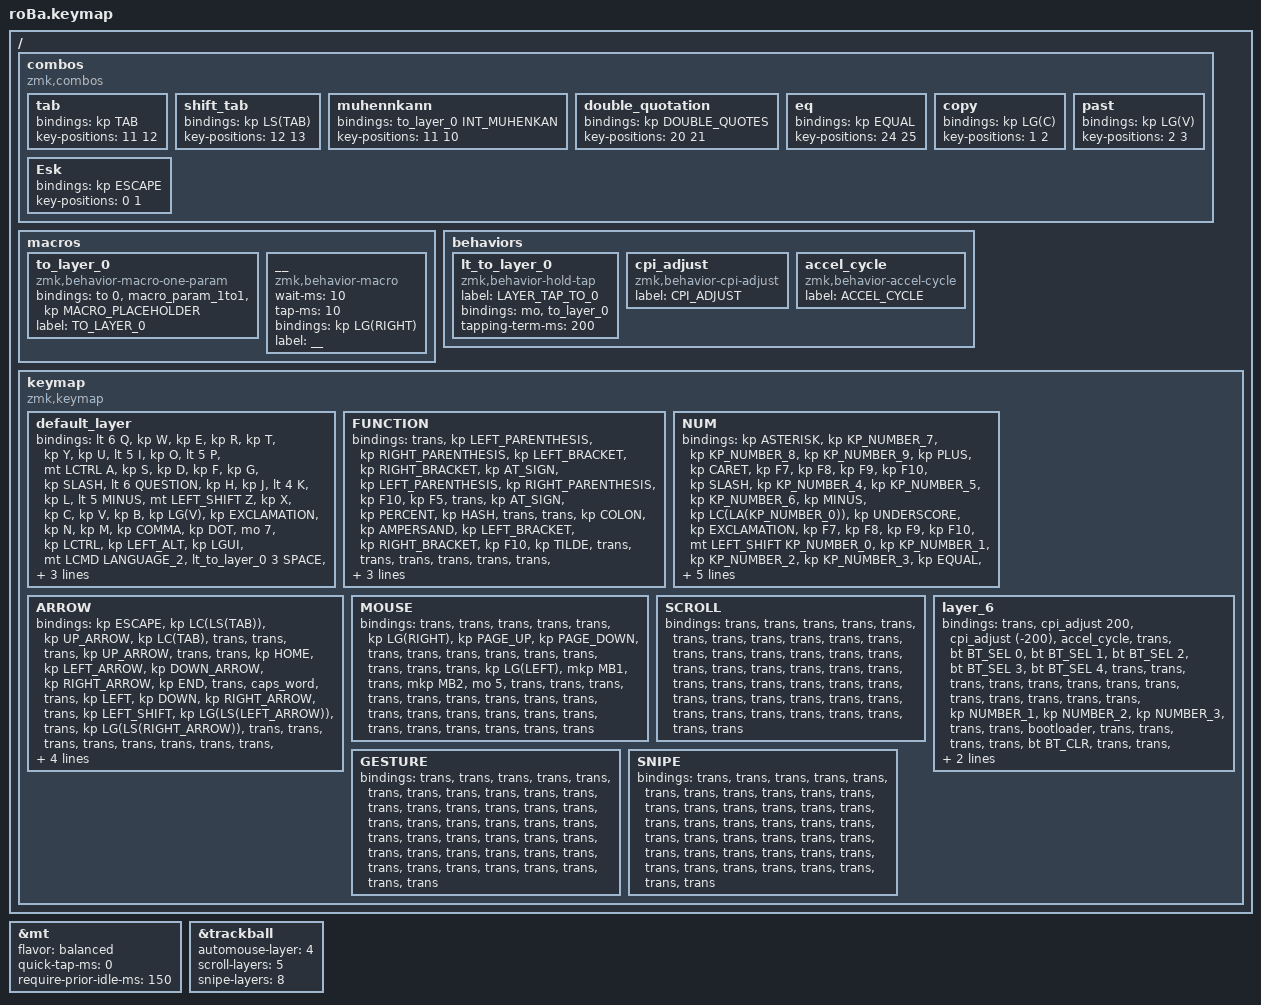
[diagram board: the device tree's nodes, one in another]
#include <behaviors.dtsi>
#include <dt-bindings/zmk/bt.h>
#include <dt-bindings/zmk/keys.h>
#include <dt-bindings/zmk/pointing.h>

&mt {
    flavor = "balanced";
    quick-tap-ms = <0>;
    // 直前のキー操作から150ms以内なら判定せず即タップ扱いにする
    // （高速タイピング中の意図しないホールド誤爆＝寿司打でZが消える問題への対策）
    require-prior-idle-ms = <150>;
};

&trackball {
    automouse-layer = <4>;
    scroll-layers = <5>;
    snipe-layers = <8>;
    // ジェスチャー(ball action)は roBa_R.overlay の trackball@0 内に定義（子ノードはoverlayが正しい置き場所）
};

/ {

    combos {
        compatible = "zmk,combos";

        tab {
            bindings = <&kp TAB>;
            key-positions = <11 12>;
        };

        shift_tab {
            bindings = <&kp LS(TAB)>;
            key-positions = <12 13>;
        };

        muhennkann {
            bindings = <&to_layer_0 INT_MUHENKAN>;
            key-positions = <11 10>;
        };

        double_quotation {
            bindings = <&kp DOUBLE_QUOTES>;
            key-positions = <20 21>;
        };

        eq {
            bindings = <&kp EQUAL>;
            key-positions = <24 25>;
        };

        copy {
            bindings = <&kp LG(C)>;
            key-positions = <1 2>;
        };

        past {
            bindings = <&kp LG(V)>;
            key-positions = <2 3>;
        };

        Esk {
            bindings = <&kp ESCAPE>;
            key-positions = <0 1>;
        };

    };

    macros {
        to_layer_0: to_layer_0 {
            compatible = "zmk,behavior-macro-one-param";
            #binding-cells = <1>;
            bindings = <&to 0 &macro_param_1to1 &kp MACRO_PLACEHOLDER>;
            label = "TO_LAYER_0";
        };
        __: __ {
            compatible = "zmk,behavior-macro";
            #binding-cells = <0>;
            wait-ms = <10>;
            tap-ms = <10>;
            bindings = <&kp LG(RIGHT)>;
            label = "__";
        };
    };

    behaviors {
        lt_to_layer_0: lt_to_layer_0 {
            compatible = "zmk,behavior-hold-tap";
            label = "LAYER_TAP_TO_0";
            bindings = <&mo>, <&to_layer_0>;

            #binding-cells = <2>;
            tapping-term-ms = <200>;
        };

        cpi_adjust: cpi_adjust {
            compatible = "zmk,behavior-cpi-adjust";
            label = "CPI_ADJUST";
            #binding-cells = <1>;
        };

        accel_cycle: accel_cycle {
            compatible = "zmk,behavior-accel-cycle";
            label = "ACCEL_CYCLE";
            #binding-cells = <0>;
        };
    };

    keymap {
        compatible = "zmk,keymap";

        default_layer {
            bindings = <
                &lt 6 Q  &kp W  &kp E  &kp R  &kp T  &kp Y  &kp U  &lt 5 I  &kp O  &lt 5 P  &mt LCTRL A  &kp S  &kp D  &kp F  &kp G  &kp SLASH  &lt 6 QUESTION  &kp H  &kp J  &lt 4 K  &kp L  &lt 5 MINUS  &mt LEFT_SHIFT Z  &kp X  &kp C  &kp V  &kp B  &kp LG(V)  &kp EXCLAMATION  &kp N  &kp M  &kp COMMA  &kp DOT  &mo 7  &kp LCTRL  &kp LEFT_ALT  &kp LGUI  &mt LCMD LANGUAGE_2  &lt_to_layer_0 3 SPACE  &lt_to_layer_0 1 LANG1  &kp BACKSPACE  &lt 2 ENTER  &mo 8
            >;
            sensor-bindings = <&inc_dec_kp PG_UP PAGE_DOWN>;
        };

        FUNCTION {
            bindings = <
                &trans  &kp LEFT_PARENTHESIS  &kp RIGHT_PARENTHESIS  &kp LEFT_BRACKET  &kp RIGHT_BRACKET  &kp AT_SIGN  &kp LEFT_PARENTHESIS  &kp RIGHT_PARENTHESIS  &kp F10  &kp F5  &trans  &kp AT_SIGN  &kp PERCENT  &kp HASH  &trans  &trans  &kp COLON  &kp AMPERSAND  &kp LEFT_BRACKET  &kp RIGHT_BRACKET  &kp F10  &kp TILDE  &trans  &trans  &trans  &trans  &trans  &trans  &kp SEMICOLON  &kp UNDERSCORE  &trans  &trans  &trans  &kp F11  &trans  &trans  &trans  &trans  &trans  &trans  &trans  &trans  &kp F12
            >;
        };

        NUM {
            bindings = <
                &kp ASTERISK  &kp KP_NUMBER_7  &kp KP_NUMBER_8  &kp KP_NUMBER_9  &kp PLUS  &kp CARET  &kp F7  &kp F8  &kp F9  &kp F10  &kp SLASH  &kp KP_NUMBER_4  &kp KP_NUMBER_5  &kp KP_NUMBER_6  &kp MINUS  &kp LC(LA(KP_NUMBER_0))  &kp UNDERSCORE  &kp EXCLAMATION  &kp F7  &kp F8  &kp F9  &kp F10  &mt LEFT_SHIFT KP_NUMBER_0  &kp KP_NUMBER_1  &kp KP_NUMBER_2  &kp KP_NUMBER_3  &kp EQUAL  &kp EQUAL  &kp COLON  &kp LEFT_BRACKET  &kp RIGHT_BRACKET  &kp LEFT_BRACE  &kp RIGHT_BRACE  &kp BACKSLASH  &trans  &trans  &trans  &kp KP_NUMBER_0  &trans  &trans  &trans  &trans  &kp PIPE
            >;
        };

        ARROW {
            bindings = <
                &kp ESCAPE  &kp LC(LS(TAB))  &kp UP_ARROW  &kp LC(TAB)  &trans  &trans  &trans  &kp UP_ARROW  &trans  &trans  &kp HOME  &kp LEFT_ARROW  &kp DOWN_ARROW  &kp RIGHT_ARROW  &kp END  &trans  &caps_word  &trans  &kp LEFT  &kp DOWN  &kp RIGHT_ARROW  &trans  &kp LEFT_SHIFT  &kp LG(LS(LEFT_ARROW))  &trans  &kp LG(LS(RIGHT_ARROW))  &trans  &trans  &trans  &trans  &trans  &trans  &trans  &trans  &trans  &trans  &trans  &trans  &trans  &trans  &trans  &trans  &trans
            >;
            sensor-bindings = <&inc_dec_kp LC(PAGE_UP) LC(PAGE_DOWN)>;
        };

        MOUSE {
            bindings = <
                &trans  &trans  &trans  &trans  &trans  &kp LG(RIGHT)  &kp PAGE_UP  &kp PAGE_DOWN  &trans  &trans  &trans  &trans  &trans  &trans  &trans  &trans  &trans  &kp LG(LEFT)  &mkp MB1  &trans  &mkp MB2  &mo 5  &trans  &trans  &trans  &trans  &trans  &trans  &trans  &trans  &trans  &trans  &trans  &trans  &trans  &trans  &trans  &trans  &trans  &trans  &trans  &trans  &trans
            >;
        };

        SCROLL {
            bindings = <
                &trans  &trans  &trans  &trans  &trans  &trans  &trans  &trans  &trans  &trans  &trans  &trans  &trans  &trans  &trans  &trans  &trans  &trans  &trans  &trans  &trans  &trans  &trans  &trans  &trans  &trans  &trans  &trans  &trans  &trans  &trans  &trans  &trans  &trans  &trans  &trans  &trans  &trans  &trans  &trans  &trans  &trans  &trans
            >;
        };

        layer_6 {
            bindings = <
                &trans  &cpi_adjust 200  &cpi_adjust (-200)  &accel_cycle  &trans  &bt BT_SEL 0  &bt BT_SEL 1  &bt BT_SEL 2  &bt BT_SEL 3  &bt BT_SEL 4  &trans  &trans  &trans  &trans  &trans  &trans  &trans  &trans  &trans  &trans  &trans  &trans  &trans  &kp NUMBER_1  &kp NUMBER_2  &kp NUMBER_3  &trans  &trans  &bootloader  &trans  &trans  &trans  &trans  &bt BT_CLR  &trans  &trans  &trans  &trans  &trans  &trans  &trans  &trans  &bt BT_CLR_ALL
            >;
        };

        GESTURE {
            bindings = <
                &trans  &trans  &trans  &trans  &trans  &trans  &trans  &trans  &trans  &trans  &trans  &trans  &trans  &trans  &trans  &trans  &trans  &trans  &trans  &trans  &trans  &trans  &trans  &trans  &trans  &trans  &trans  &trans  &trans  &trans  &trans  &trans  &trans  &trans  &trans  &trans  &trans  &trans  &trans  &trans  &trans  &trans  &trans
            >;
        };

        SNIPE {
            bindings = <
                &trans  &trans  &trans  &trans  &trans  &trans  &trans  &trans  &trans  &trans  &trans  &trans  &trans  &trans  &trans  &trans  &trans  &trans  &trans  &trans  &trans  &trans  &trans  &trans  &trans  &trans  &trans  &trans  &trans  &trans  &trans  &trans  &trans  &trans  &trans  &trans  &trans  &trans  &trans  &trans  &trans  &trans  &trans
            >;
        };

    };
};
